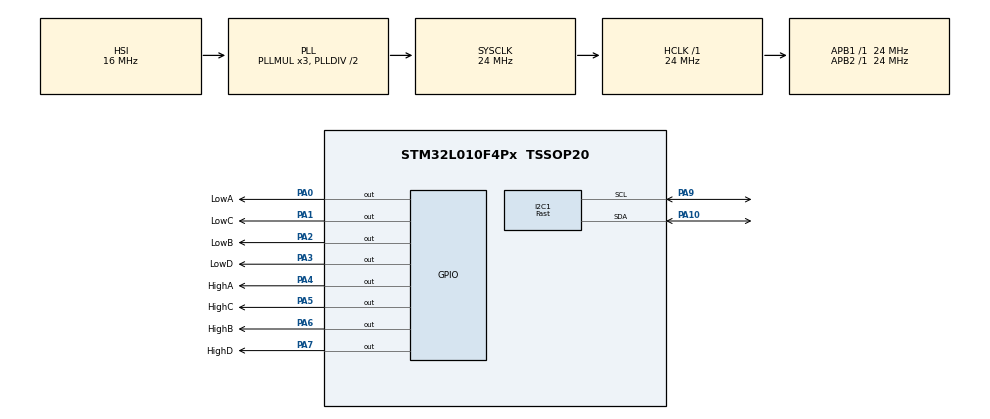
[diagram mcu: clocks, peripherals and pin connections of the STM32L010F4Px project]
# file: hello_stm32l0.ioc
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I2C1.I2C_Speed_Mode=I2C_Fast
I2C1.Timing=0x00200C28
Mcu.Family=STM32L0
Mcu.Name=STM32L010F4Px
Mcu.Package=TSSOP20
NVIC.TIM2_IRQn=true\:0\:0\:false\:false\:true\:true\:true
PA0-CK_IN.GPIO_Label=LowA
PA0-CK_IN.Signal=GPIO_Output
PA1.GPIO_Label=LowC
PA1.Signal=GPIO_Output
PA10.Mode=I2C
PA10.Signal=I2C1_SDA
PA2.GPIO_Label=LowB
PA2.Signal=GPIO_Output
PA3.GPIO_Label=LowD
PA3.Signal=GPIO_Output
PA4.GPIO_Label=HighA
PA4.Signal=GPIO_Output
PA5.GPIO_Label=HighC
PA5.Signal=GPIO_Output
PA6.GPIO_Label=HighB
PA6.Signal=GPIO_Output
PA7.GPIO_Label=HighD
PA7.Signal=GPIO_Output
PA9.Mode=I2C
PA9.Signal=I2C1_SCL
PB1.Signal=S_TIM2_CH4
ProjectManager.HeapSize=0x200
ProjectManager.StackSize=0x400
ProjectManager.TargetToolchain=STM32CubeIDE
RCC.ADCFreq_Value=16000000
RCC.AHBFreq_Value=24000000
RCC.APB1Freq_Value=24000000
RCC.APB1TimFreq_Value=24000000
RCC.APB2Freq_Value=24000000
RCC.APB2TimFreq_Value=24000000
RCC.HCLKFreq_Value=24000000
RCC.HSE_VALUE=8000000
RCC.HSI16_VALUE=16000000
RCC.HSI_VALUE=16000000
RCC.LSE_VALUE=32768
RCC.MSI_VALUE=2097000
RCC.SYSCLKFreq_VALUE=24000000
RCC.SYSCLKSource=RCC_SYSCLKSOURCE_PLLCLK
RCC.VCOOutputFreq_Value=48000000
SH.S_TIM2_CH4.0=TIM2_CH4
TIM2.AutoReloadPreload=TIM_AUTORELOAD_PRELOAD_ENABLE
TIM2.Channel-Output\ Compare1\ No\ Output=TIM_CHANNEL_1
TIM2.Period=19999
TIM2.Prescaler=0
VP_TIM2_VS_ClockSourceINT.Mode=Internal
VP_TIM2_VS_no_output1.Mode=Output Compare1 No Output
board=custom

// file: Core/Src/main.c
/* USER CODE BEGIN Header */
/**
 ******************************************************************************
 * @file           : main.c
 * @brief          : Main program body
 ******************************************************************************
 * @attention
 *
 * <h2><center>&copy; Copyright (c) 2021 STMicroelectronics.
 * All rights reserved.</center></h2>
 *
 * This software component is licensed by ST under BSD 3-Clause license,
 * the "License"; You may not use this file except in compliance with the
 * License. You may obtain a copy of the License at:
 *                        opensource.org/licenses/BSD-3-Clause
 *
 ******************************************************************************
 */
/* USER CODE END Header */
#include "main.h"

I2C_HandleTypeDef hi2c1;

TIM_HandleTypeDef htim2;

void SystemClock_Config(void);
static void MX_GPIO_Init(void);
static void MX_I2C1_Init(void);
static void MX_TIM2_Init(void);
/* USER CODE BEGIN PFP */

extern void application_setup();
extern void application_loop();

/* USER CODE END PFP */

int main(void)
{

  /* MCU Configuration--------------------------------------------------------*/

  /* Reset of all peripherals, Initializes the Flash interface and the Systick. */
  HAL_Init();

  /* Configure the system clock */
  SystemClock_Config();

  /* Initialize all configured peripherals */
  MX_GPIO_Init();
  MX_I2C1_Init();
  MX_TIM2_Init();
  /* USER CODE BEGIN 2 */
  application_setup();
  /* USER CODE END 2 */

  /* Infinite loop */
  while (1) {

    /* USER CODE BEGIN 3 */
    application_loop();
  }
  /* USER CODE END 3 */
}

void SystemClock_Config(void)
{
  RCC_OscInitTypeDef RCC_OscInitStruct = {0};
  RCC_ClkInitTypeDef RCC_ClkInitStruct = {0};
  RCC_PeriphCLKInitTypeDef PeriphClkInit = {0};

  /** Configure the main internal regulator output voltage
  */
  __HAL_PWR_VOLTAGESCALING_CONFIG(PWR_REGULATOR_VOLTAGE_SCALE1);
  /** Initializes the RCC Oscillators according to the specified parameters
  * in the RCC_OscInitTypeDef structure.
  */
  RCC_OscInitStruct.OscillatorType = RCC_OSCILLATORTYPE_HSI;
  RCC_OscInitStruct.HSIState = RCC_HSI_ON;
  RCC_OscInitStruct.HSICalibrationValue = RCC_HSICALIBRATION_DEFAULT;
  RCC_OscInitStruct.PLL.PLLState = RCC_PLL_ON;
  RCC_OscInitStruct.PLL.PLLSource = RCC_PLLSOURCE_HSI;
  RCC_OscInitStruct.PLL.PLLMUL = RCC_PLLMUL_3;
  RCC_OscInitStruct.PLL.PLLDIV = RCC_PLLDIV_2;
  if (HAL_RCC_OscConfig(&RCC_OscInitStruct) != HAL_OK)
  {
    Error_Handler();
  }
  /** Initializes the CPU, AHB and APB buses clocks
  */
  RCC_ClkInitStruct.ClockType = RCC_CLOCKTYPE_HCLK|RCC_CLOCKTYPE_SYSCLK
                              |RCC_CLOCKTYPE_PCLK1|RCC_CLOCKTYPE_PCLK2;
  RCC_ClkInitStruct.SYSCLKSource = RCC_SYSCLKSOURCE_PLLCLK;
  RCC_ClkInitStruct.AHBCLKDivider = RCC_SYSCLK_DIV1;
  RCC_ClkInitStruct.APB1CLKDivider = RCC_HCLK_DIV1;
  RCC_ClkInitStruct.APB2CLKDivider = RCC_HCLK_DIV1;

  if (HAL_RCC_ClockConfig(&RCC_ClkInitStruct, FLASH_LATENCY_1) != HAL_OK)
  {
    Error_Handler();
  }
  PeriphClkInit.PeriphClockSelection = RCC_PERIPHCLK_I2C1;
  PeriphClkInit.I2c1ClockSelection = RCC_I2C1CLKSOURCE_PCLK1;
  if (HAL_RCCEx_PeriphCLKConfig(&PeriphClkInit) != HAL_OK)
  {
    Error_Handler();
  }
}

static void MX_I2C1_Init(void)
{

  hi2c1.Instance = I2C1;
  hi2c1.Init.Timing = 0x00200C28;
  hi2c1.Init.OwnAddress1 = 0;
  hi2c1.Init.AddressingMode = I2C_ADDRESSINGMODE_7BIT;
  hi2c1.Init.DualAddressMode = I2C_DUALADDRESS_DISABLE;
  hi2c1.Init.OwnAddress2 = 0;
  hi2c1.Init.OwnAddress2Masks = I2C_OA2_NOMASK;
  hi2c1.Init.GeneralCallMode = I2C_GENERALCALL_DISABLE;
  hi2c1.Init.NoStretchMode = I2C_NOSTRETCH_DISABLE;
  if (HAL_I2C_Init(&hi2c1) != HAL_OK)
  {
    Error_Handler();
  }
  /** Configure Analogue filter
  */
  if (HAL_I2CEx_ConfigAnalogFilter(&hi2c1, I2C_ANALOGFILTER_ENABLE) != HAL_OK)
  {
    Error_Handler();
  }
  /** Configure Digital filter
  */
  if (HAL_I2CEx_ConfigDigitalFilter(&hi2c1, 0) != HAL_OK)
  {
    Error_Handler();
  }

}

static void MX_TIM2_Init(void)
{

  TIM_ClockConfigTypeDef sClockSourceConfig = {0};
  TIM_MasterConfigTypeDef sMasterConfig = {0};
  TIM_OC_InitTypeDef sConfigOC = {0};

  htim2.Instance = TIM2;
  htim2.Init.Prescaler = 0;
  htim2.Init.CounterMode = TIM_COUNTERMODE_UP;
  htim2.Init.Period = 19999;
  htim2.Init.ClockDivision = TIM_CLOCKDIVISION_DIV1;
  htim2.Init.AutoReloadPreload = TIM_AUTORELOAD_PRELOAD_ENABLE;
  if (HAL_TIM_Base_Init(&htim2) != HAL_OK)
  {
    Error_Handler();
  }
  sClockSourceConfig.ClockSource = TIM_CLOCKSOURCE_INTERNAL;
  if (HAL_TIM_ConfigClockSource(&htim2, &sClockSourceConfig) != HAL_OK)
  {
    Error_Handler();
  }
  if (HAL_TIM_OC_Init(&htim2) != HAL_OK)
  {
    Error_Handler();
  }
  sMasterConfig.MasterOutputTrigger = TIM_TRGO_RESET;
  sMasterConfig.MasterSlaveMode = TIM_MASTERSLAVEMODE_DISABLE;
  if (HAL_TIMEx_MasterConfigSynchronization(&htim2, &sMasterConfig) != HAL_OK)
  {
    Error_Handler();
  }
  sConfigOC.OCMode = TIM_OCMODE_TIMING;
  sConfigOC.Pulse = 0;
  sConfigOC.OCPolarity = TIM_OCPOLARITY_HIGH;
  sConfigOC.OCFastMode = TIM_OCFAST_DISABLE;
  if (HAL_TIM_OC_ConfigChannel(&htim2, &sConfigOC, TIM_CHANNEL_1) != HAL_OK)
  {
    Error_Handler();
  }

}

static void MX_GPIO_Init(void)
{
  GPIO_InitTypeDef GPIO_InitStruct = {0};

  /* GPIO Ports Clock Enable */
  __HAL_RCC_GPIOA_CLK_ENABLE();
  __HAL_RCC_GPIOB_CLK_ENABLE();

  /*Configure GPIO pin Output Level */
  HAL_GPIO_WritePin(GPIOA, LowA_Pin|LowC_Pin|LowB_Pin|LowD_Pin
                          |HighA_Pin|HighC_Pin|HighB_Pin|HighD_Pin, GPIO_PIN_RESET);

  /*Configure GPIO pins : LowA_Pin LowC_Pin LowB_Pin LowD_Pin
                           HighA_Pin HighC_Pin HighB_Pin HighD_Pin */
  GPIO_InitStruct.Pin = LowA_Pin|LowC_Pin|LowB_Pin|LowD_Pin
                          |HighA_Pin|HighC_Pin|HighB_Pin|HighD_Pin;
  GPIO_InitStruct.Mode = GPIO_MODE_OUTPUT_PP;
  GPIO_InitStruct.Pull = GPIO_NOPULL;
  GPIO_InitStruct.Speed = GPIO_SPEED_FREQ_LOW;
  HAL_GPIO_Init(GPIOA, &GPIO_InitStruct);

}

void Error_Handler(void)
{
  __disable_irq();
  while (1) {
  }
}

#ifdef  USE_FULL_ASSERT
/**
  * @brief  Reports the name of the source file and the source line number
  *         where the assert_param error has occurred.
  * @param  file: pointer to the source file name
  * @param  line: assert_param error line source number
  * @retval None
  */
void assert_failed(uint8_t *file, uint32_t line)
{
  /* USER CODE BEGIN 6 */
  /* User can add his own implementation to report the file name and line
     number,
     ex: printf("Wrong parameters value: file %s on line %d\r\n", file, line) */
  /* USER CODE END 6 */
}
#endif /* USE_FULL_ASSERT */
